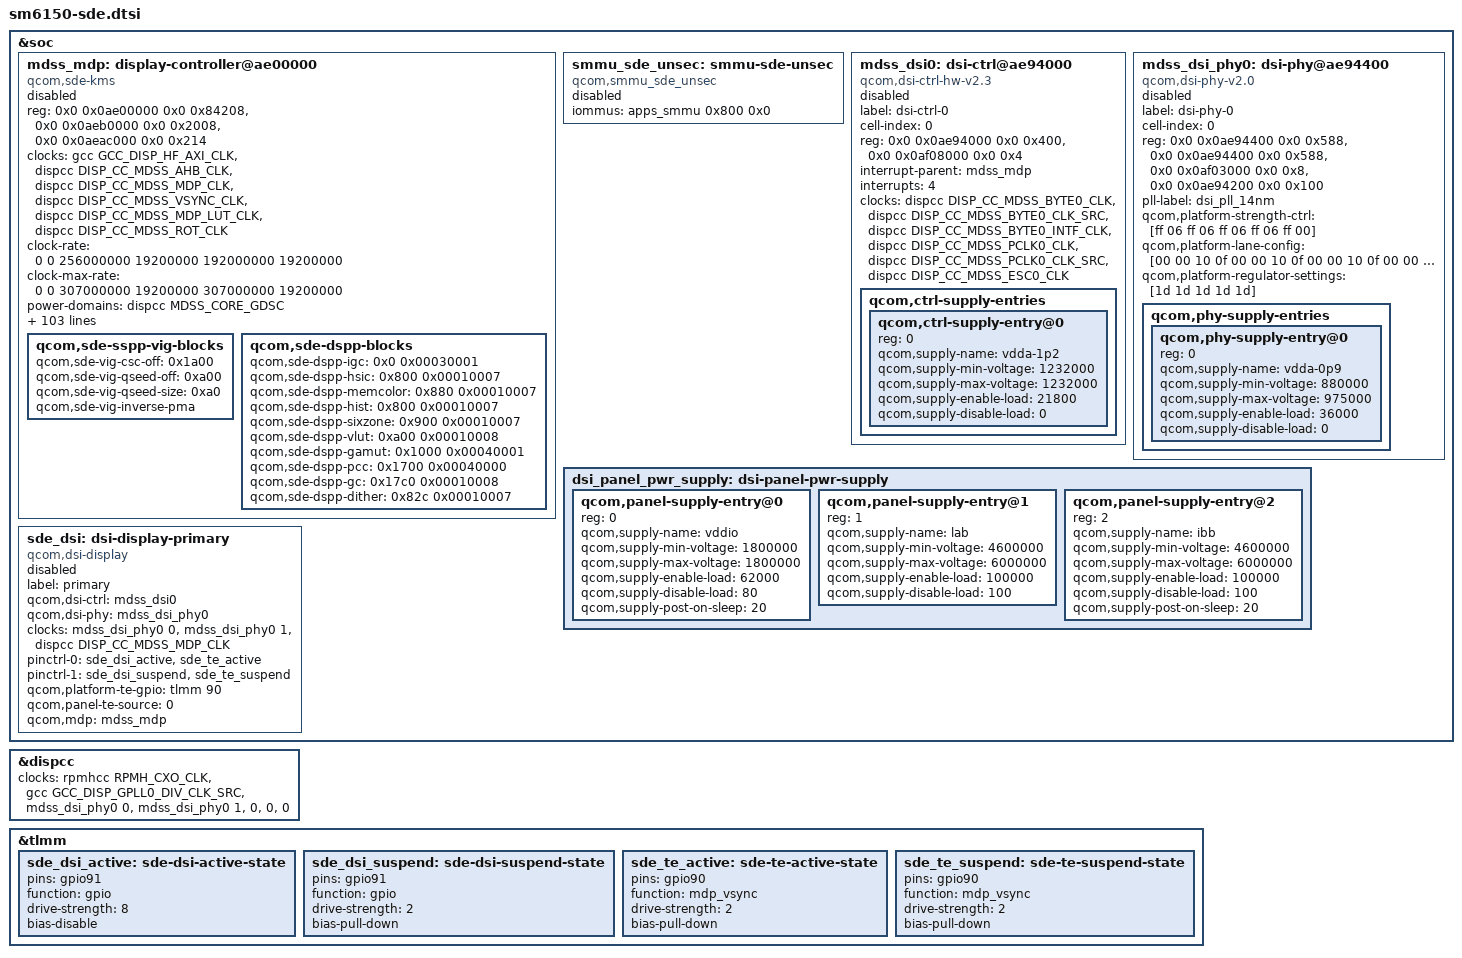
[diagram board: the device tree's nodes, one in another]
// SPDX-License-Identifier: BSD-3-Clause
/*
 * SM6150 display subsystem for the downstream display driver
 * (techpack/display). Hardware values from msm-4.14 sm6150-sde.dtsi.
 *
 * The SDE RSC, the rotator, writeback and DisplayPort are left out: the
 * driver is built without them.
 */

&soc {
	mdss_mdp: display-controller@ae00000 {
		compatible = "qcom,sde-kms";
		reg = <0x0 0x0ae00000 0x0 0x84208>,
		      <0x0 0x0aeb0000 0x0 0x2008>,
		      <0x0 0x0aeac000 0x0 0x214>;
		reg-names = "mdp_phys",
			    "vbif_phys",
			    "regdma_phys";

		clocks = <&gcc GCC_DISP_HF_AXI_CLK>,
			 <&dispcc DISP_CC_MDSS_AHB_CLK>,
			 <&dispcc DISP_CC_MDSS_MDP_CLK>,
			 <&dispcc DISP_CC_MDSS_VSYNC_CLK>,
			 <&dispcc DISP_CC_MDSS_MDP_LUT_CLK>,
			 <&dispcc DISP_CC_MDSS_ROT_CLK>;
		clock-names = "gcc_bus",
			      "iface_clk",
			      "core_clk",
			      "vsync_clk",
			      "lut_clk",
			      "rot_clk";
		clock-rate = <0 0 256000000 19200000 192000000 19200000>;
		clock-max-rate = <0 0 307000000 19200000 307000000 19200000>;

		/* The MDSS GDSC is a power domain here, not a regulator */
		power-domains = <&dispcc MDSS_CORE_GDSC>;

		interrupts = <GIC_SPI 83 IRQ_TYPE_LEVEL_HIGH>;
		interrupt-controller;
		#interrupt-cells = <1>;

		interconnects = <&mmss_noc MASTER_MDP0 QCOM_ICC_TAG_ALWAYS
				 &mc_virt SLAVE_EBI1 QCOM_ICC_TAG_ALWAYS>,
				<&gem_noc MASTER_APPSS_PROC QCOM_ICC_TAG_ACTIVE_ONLY
				 &config_noc SLAVE_DISPLAY_CFG QCOM_ICC_TAG_ACTIVE_ONLY>;
		interconnect-names = "qcom,sde-data-bus0",
				     "qcom,sde-reg-bus";

		qcom,sde-reg-bus,vectors-KBps = <0 0>,
						<0 76800>,
						<0 150000>,
						<0 300000>;

		#address-cells = <1>;
		#size-cells = <0>;

		connectors = <&sde_dsi &smmu_sde_unsec>;

		/* hw blocks */
		qcom,sde-off = <0x1000>;
		qcom,sde-len = <0x45c>;

		qcom,sde-ctl-off = <0x2000 0x2200 0x2400
				    0x2600 0x2800 0x2a00>;
		qcom,sde-ctl-size = <0x1e0>;
		qcom,sde-ctl-display-pref = "primary", "none", "none",
					    "none", "none", "none";

		qcom,sde-mixer-off = <0x45000 0x46000 0x47000
				      0x0 0x0 0x0>;
		qcom,sde-mixer-size = <0x320>;
		qcom,sde-mixer-display-pref = "primary", "none", "none",
					      "none", "none", "none";
		qcom,sde-mixer-cwb-pref = "none", "none", "cwb",
					  "none", "none", "none";

		qcom,sde-dspp-top-off = <0x1300>;
		qcom,sde-dspp-top-size = <0x80>;
		qcom,sde-dspp-off = <0x55000>;
		qcom,sde-dspp-size = <0x1800>;

		qcom,sde-intf-off = <0x6b000 0x6b800 0x6c000 0x6c800>;
		qcom,sde-intf-size = <0x2b8>;
		qcom,sde-intf-type = "dp", "dsi", "none", "dp";

		qcom,sde-pp-off = <0x71000 0x71800 0x72000>;
		qcom,sde-pp-slave = <0x0 0x0 0x0>;
		qcom,sde-pp-size = <0xd4>;

		qcom,sde-te2-off = <0x2000 0x2000 0x0>;

		qcom,sde-cdm-off = <0x7a200>;
		qcom,sde-cdm-size = <0x224>;

		qcom,sde-dither-off = <0x30e0 0x30e0 0x30e0 0x30e0>;
		qcom,sde-dither-version = <0x00010000>;
		qcom,sde-dither-size = <0x20>;

		qcom,sde-sspp-type = "vig", "dma", "dma", "dma", "dma";
		qcom,sde-sspp-off = <0x5000 0x25000 0x27000 0x29000 0x2b000>;
		qcom,sde-sspp-src-size = <0x1f0>;
		qcom,sde-sspp-xin-id = <0 1 5 9 13>;
		qcom,sde-sspp-excl-rect = <1 1 1 1 1>;
		qcom,sde-sspp-smart-dma-priority = <5 1 2 3 4>;
		qcom,sde-smart-dma-rev = "smart_dma_v2p5";

		qcom,sde-mixer-pair-mask = <3 0 1 0 0 0>;

		qcom,sde-mixer-blend-op-off = <0x20 0x38 0x50 0x68 0x80 0x98
					       0xb0 0xc8 0xe0 0xf8 0x110>;

		qcom,sde-max-per-pipe-bw-kbps = <4500000 4500000 4500000
						 4500000 4500000>;

		/* offsets are relative to "mdp_phys + qcom,sde-off */
		qcom,sde-sspp-clk-ctrl = <0x2ac 0>, <0x2ac 8>, <0x2b4 8>,
					 <0x2bc 8>, <0x2c4 8>;
		qcom,sde-sspp-csc-off = <0x1a00>;
		qcom,sde-csc-type = "csc-10bit";
		qcom,sde-qseed-sw-lib-rev = "qseedv3lite";
		qcom,sde-qseed-scalar-version = <0x3000>;
		qcom,sde-sspp-qseed-off = <0xa00>;
		qcom,sde-mixer-linewidth = <2560>;
		qcom,sde-sspp-linewidth = <2160>;
		qcom,sde-wb-linewidth = <2160>;
		qcom,sde-mixer-blendstages = <0x9>;
		/* <DDR type (0: any), highest bank bit - 13> */
		qcom,sde-highest-bank-bit = <0x0 0x1>;
		qcom,sde-ubwc-version = <0x200>;
		qcom,sde-panic-per-pipe;
		qcom,sde-has-cdp;
		qcom,sde-has-dim-layer;
		qcom,sde-has-idle-pc;

		qcom,sde-max-bw-low-kbps = <4800000>;
		qcom,sde-max-bw-high-kbps = <4800000>;
		qcom,sde-min-core-ib-kbps = <2400000>;
		qcom,sde-min-llcc-ib-kbps = <800000>;
		qcom,sde-min-dram-ib-kbps = <800000>;
		qcom,sde-dram-channels = <2>;
		qcom,sde-num-nrt-paths = <0>;

		qcom,sde-vbif-off = <0>;
		qcom,sde-vbif-size = <0x1040>;
		qcom,sde-vbif-id = <0>;
		qcom,sde-vbif-memtype-0 = <3 3 3 3 3 3 3 3>;
		qcom,sde-vbif-memtype-1 = <3 3 3 3 3 3>;
		qcom,sde-vbif-qos-rt-remap = <3 3 4 4 5 5 6 6>;
		qcom,sde-vbif-qos-nrt-remap = <3 3 3 3 3 3 3 3>;

		/*
		 * One set of LUTs, for 60 fps, in the order linear, macrotile,
		 * nrt, cwb, macrotile-qseed, linear-qseed. msm-4.14 has no
		 * linear-qseed entry, so it repeats linear.
		 */
		qcom,sde-qos-refresh-rates = <60>;
		qcom,sde-danger-lut = <0x0000000f 0x0000ffff 0x00000000
				       0x00000000 0x0000ffff 0x0000000f>;
		qcom,sde-safe-lut = <0xfff8 0xf000 0xffff 0xffff 0xf000 0xfff8>;
		qcom,sde-qos-lut-linear = <0x00112222 0x22223357>;
		qcom,sde-qos-lut-macrotile = <0x00112233 0x44556677>;
		qcom,sde-qos-lut-macrotile-qseed = <0x00112233 0x66777777>;
		qcom,sde-qos-lut-nrt = <0x00000000 0x00000000>;
		qcom,sde-qos-lut-cwb = <0x75300000 0x00000000>;

		qcom,sde-cdp-setting = <1 1>, <1 0>;

		/* offsets are relative to "mdp_phys + qcom,sde-off */
		qcom,sde-reg-dma-off = <0>;
		qcom,sde-reg-dma-version = <0x00010001>;
		qcom,sde-reg-dma-trigger-off = <0x119c>;

		qcom,sde-secure-sid-mask = <0x0000801>;

		status = "disabled";

		qcom,sde-sspp-vig-blocks {
			qcom,sde-vig-csc-off = <0x1a00>;
			qcom,sde-vig-qseed-off = <0xa00>;
			qcom,sde-vig-qseed-size = <0xa0>;
			qcom,sde-vig-inverse-pma;
		};

		qcom,sde-dspp-blocks {
			qcom,sde-dspp-igc = <0x0 0x00030001>;
			qcom,sde-dspp-hsic = <0x800 0x00010007>;
			qcom,sde-dspp-memcolor = <0x880 0x00010007>;
			qcom,sde-dspp-hist = <0x800 0x00010007>;
			qcom,sde-dspp-sixzone = <0x900 0x00010007>;
			qcom,sde-dspp-vlut = <0xa00 0x00010008>;
			qcom,sde-dspp-gamut = <0x1000 0x00040001>;
			qcom,sde-dspp-pcc = <0x1700 0x00040000>;
			qcom,sde-dspp-gc = <0x17c0 0x00010008>;
			qcom,sde-dspp-dither = <0x82c 0x00010007>;
		};
	};

	smmu_sde_unsec: smmu-sde-unsec {
		compatible = "qcom,smmu_sde_unsec";
		iommus = <&apps_smmu 0x800 0x0>;

		status = "disabled";
	};

	mdss_dsi0: dsi-ctrl@ae94000 {
		compatible = "qcom,dsi-ctrl-hw-v2.3";
		label = "dsi-ctrl-0";
		cell-index = <0>;
		reg = <0x0 0x0ae94000 0x0 0x400>,
		      <0x0 0x0af08000 0x0 0x4>;
		reg-names = "dsi_ctrl",
			    "disp_cc_base";

		interrupt-parent = <&mdss_mdp>;
		interrupts = <4>;

		clocks = <&dispcc DISP_CC_MDSS_BYTE0_CLK>,
			 <&dispcc DISP_CC_MDSS_BYTE0_CLK_SRC>,
			 <&dispcc DISP_CC_MDSS_BYTE0_INTF_CLK>,
			 <&dispcc DISP_CC_MDSS_PCLK0_CLK>,
			 <&dispcc DISP_CC_MDSS_PCLK0_CLK_SRC>,
			 <&dispcc DISP_CC_MDSS_ESC0_CLK>;
		clock-names = "byte_clk",
			      "byte_clk_rcg",
			      "byte_intf_clk",
			      "pixel_clk",
			      "pixel_clk_rcg",
			      "esc_clk";

		status = "disabled";

		qcom,ctrl-supply-entries {
			#address-cells = <1>;
			#size-cells = <0>;

			qcom,ctrl-supply-entry@0 {
				reg = <0>;
				qcom,supply-name = "vdda-1p2";
				qcom,supply-min-voltage = <1232000>;
				qcom,supply-max-voltage = <1232000>;
				qcom,supply-enable-load = <21800>;
				qcom,supply-disable-load = <0>;
			};
		};
	};

	/*
	 * The 14nm PLL registers sit in the PHY block (at +0x400), so the PHY
	 * and the PLL both map it.
	 */
	mdss_dsi_phy0: dsi-phy@ae94400 {
		compatible = "qcom,dsi-phy-v2.0";
		label = "dsi-phy-0";
		cell-index = <0>;
		reg = <0x0 0x0ae94400 0x0 0x588>,
		      <0x0 0x0ae94400 0x0 0x588>,
		      <0x0 0x0af03000 0x0 0x8>,
		      <0x0 0x0ae94200 0x0 0x100>;
		reg-names = "dsi_phy",
			    "pll_base",
			    "gdsc_base",
			    "dyn_refresh_base";
		pll-label = "dsi_pll_14nm";

		/* 0: byte clock, 1: pixel clock */
		#clock-cells = <1>;

		qcom,platform-strength-ctrl = [ff 06
					       ff 06
					       ff 06
					       ff 06
					       ff 00];
		qcom,platform-lane-config = [00 00 10 0f
					     00 00 10 0f
					     00 00 10 0f
					     00 00 10 0f
					     00 00 10 8f];
		qcom,platform-regulator-settings = [1d 1d 1d 1d 1d];

		status = "disabled";

		qcom,phy-supply-entries {
			#address-cells = <1>;
			#size-cells = <0>;

			qcom,phy-supply-entry@0 {
				reg = <0>;
				qcom,supply-name = "vdda-0p9";
				qcom,supply-min-voltage = <880000>;
				qcom,supply-max-voltage = <975000>;
				qcom,supply-enable-load = <36000>;
				qcom,supply-disable-load = <0>;
			};
		};
	};

	dsi_panel_pwr_supply: dsi-panel-pwr-supply {
		#address-cells = <1>;
		#size-cells = <0>;

		qcom,panel-supply-entry@0 {
			reg = <0>;
			qcom,supply-name = "vddio";
			qcom,supply-min-voltage = <1800000>;
			qcom,supply-max-voltage = <1800000>;
			qcom,supply-enable-load = <62000>;
			qcom,supply-disable-load = <80>;
			qcom,supply-post-on-sleep = <20>;
		};

		qcom,panel-supply-entry@1 {
			reg = <1>;
			qcom,supply-name = "lab";
			qcom,supply-min-voltage = <4600000>;
			qcom,supply-max-voltage = <6000000>;
			qcom,supply-enable-load = <100000>;
			qcom,supply-disable-load = <100>;
		};

		qcom,panel-supply-entry@2 {
			reg = <2>;
			qcom,supply-name = "ibb";
			qcom,supply-min-voltage = <4600000>;
			qcom,supply-max-voltage = <6000000>;
			qcom,supply-enable-load = <100000>;
			qcom,supply-disable-load = <100>;
			qcom,supply-post-on-sleep = <20>;
		};
	};

	sde_dsi: dsi-display-primary {
		compatible = "qcom,dsi-display";
		label = "primary";

		qcom,dsi-ctrl = <&mdss_dsi0>;
		qcom,dsi-phy = <&mdss_dsi_phy0>;

		clocks = <&mdss_dsi_phy0 0>,
			 <&mdss_dsi_phy0 1>,
			 <&dispcc DISP_CC_MDSS_MDP_CLK>;
		clock-names = "pll_byte_clk0",
			      "pll_dsi_clk0",
			      "mdp_core_clk";

		pinctrl-0 = <&sde_dsi_active &sde_te_active>;
		pinctrl-1 = <&sde_dsi_suspend &sde_te_suspend>;
		pinctrl-names = "panel_active", "panel_suspend";

		qcom,platform-te-gpio = <&tlmm 90 0>;
		qcom,panel-te-source = <0>;

		qcom,mdp = <&mdss_mdp>;

		status = "disabled";
	};
};

&dispcc {
	clocks = <&rpmhcc RPMH_CXO_CLK>,
		 <&gcc GCC_DISP_GPLL0_DIV_CLK_SRC>,
		 <&mdss_dsi_phy0 0>,
		 <&mdss_dsi_phy0 1>,
		 <0>,
		 <0>,
		 <0>;
};

&tlmm {
	sde_dsi_active: sde-dsi-active-state {
		pins = "gpio91";
		function = "gpio";
		drive-strength = <8>;
		bias-disable;
	};

	sde_dsi_suspend: sde-dsi-suspend-state {
		pins = "gpio91";
		function = "gpio";
		drive-strength = <2>;
		bias-pull-down;
	};

	sde_te_active: sde-te-active-state {
		pins = "gpio90";
		function = "mdp_vsync";
		drive-strength = <2>;
		bias-pull-down;
	};

	sde_te_suspend: sde-te-suspend-state {
		pins = "gpio90";
		function = "mdp_vsync";
		drive-strength = <2>;
		bias-pull-down;
	};
};
